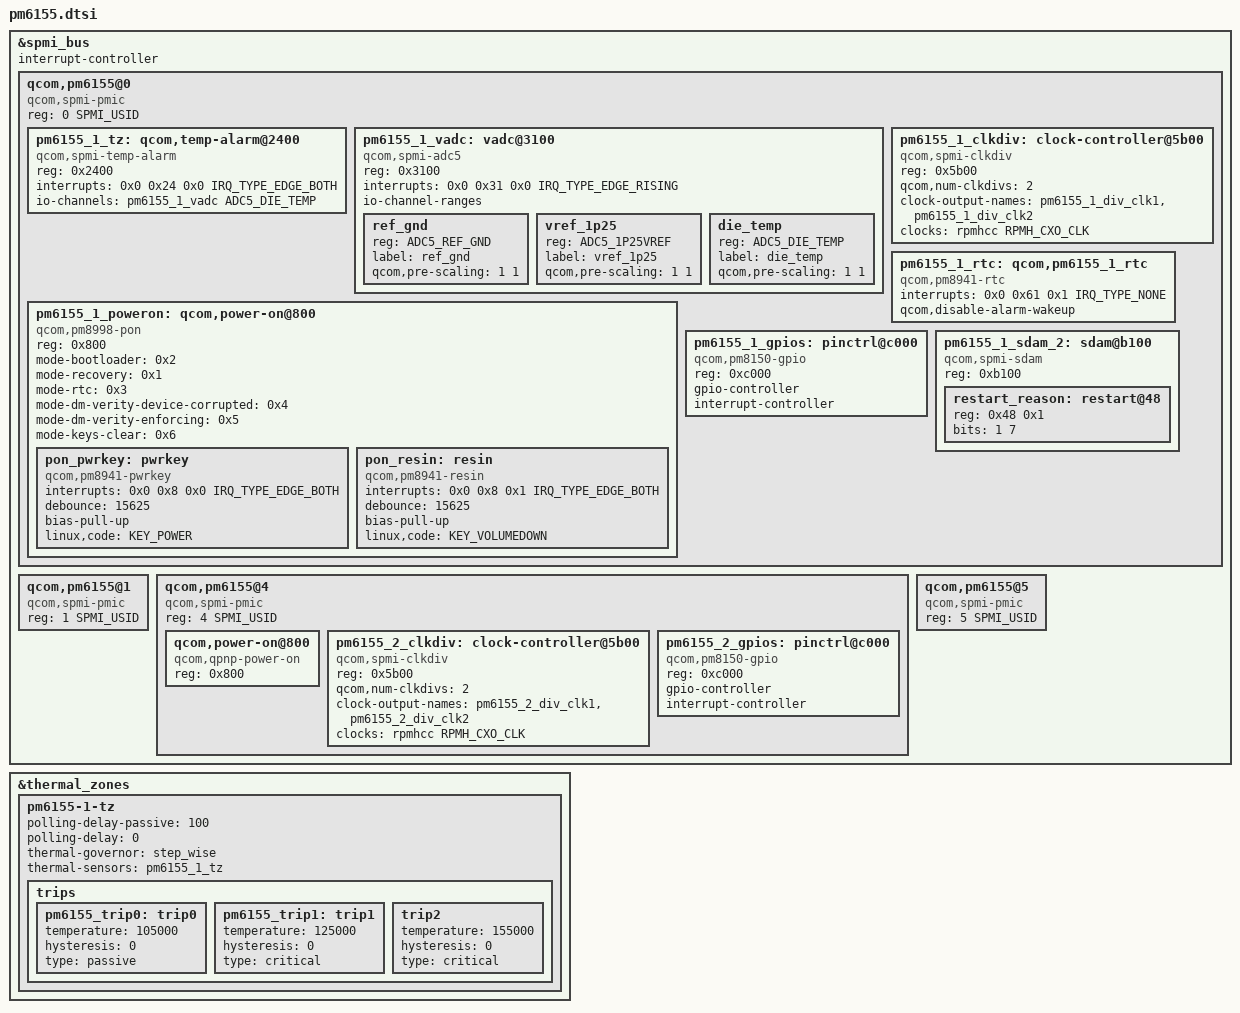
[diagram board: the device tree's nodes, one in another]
#include <dt-bindings/clock/qcom,rpmh.h>
#include <dt-bindings/input/input.h>
#include <dt-bindings/input/qcom,qpnp-power-on.h>
#include <dt-bindings/interrupt-controller/irq.h>
#include <dt-bindings/spmi/spmi.h>
#include <dt-bindings/iio/qcom,spmi-vadc.h>

&spmi_bus {
	#address-cells = <2>;
	#size-cells = <0>;
	interrupt-controller;
	#interrupt-cells = <4>;

	qcom,pm6155@0 {
		compatible = "qcom,spmi-pmic";
		reg = <0 SPMI_USID>;
		#address-cells = <1>;
		#size-cells = <0>;

		pm6155_1_tz: qcom,temp-alarm@2400 {
			compatible = "qcom,spmi-temp-alarm";
			reg = <0x2400>;
			interrupts = <0x0 0x24 0x0 IRQ_TYPE_EDGE_BOTH>;
			io-channels = <&pm6155_1_vadc ADC5_DIE_TEMP>;
			io-channel-names = "thermal";
			#thermal-sensor-cells = <0>;
		};

		pm6155_1_vadc: vadc@3100 {
			compatible = "qcom,spmi-adc5";
			reg = <0x3100>;
			#address-cells = <1>;
			#size-cells = <0>;
			interrupts = <0x0 0x31 0x0 IRQ_TYPE_EDGE_RISING>;
			interrupt-names = "eoc-int-en-set";
			#io-channel-cells = <1>;
			io-channel-ranges;

			/* Channel node */
			ref_gnd {
				reg = <ADC5_REF_GND>;
				label = "ref_gnd";
				qcom,pre-scaling = <1 1>;
			};

			vref_1p25 {
				reg = <ADC5_1P25VREF>;
				label = "vref_1p25";
				qcom,pre-scaling = <1 1>;
			};

			die_temp {
				reg = <ADC5_DIE_TEMP>;
				label = "die_temp";
				qcom,pre-scaling = <1 1>;
			};
		};

		pm6155_1_poweron: qcom,power-on@800 {
			compatible = "qcom,pm8998-pon";
			reg = <0x800>;
			mode-bootloader = <0x2>;
			mode-recovery = <0x1>;
			mode-rtc = <0x3>;
			mode-dm-verity-device-corrupted = <0x4>;
			mode-dm-verity-enforcing = <0x5>;
			mode-keys-clear = <0x6>;

			pon_pwrkey: pwrkey {
				compatible = "qcom,pm8941-pwrkey";
				interrupts = <0x0 0x8 0x0 IRQ_TYPE_EDGE_BOTH>;
				debounce = <15625>;
				bias-pull-up;
				linux,code = <KEY_POWER>;
			};

			pon_resin: resin {
				compatible = "qcom,pm8941-resin";
				interrupts = <0x0 0x8 0x1 IRQ_TYPE_EDGE_BOTH>;
				debounce = <15625>;
				bias-pull-up;
				linux,code = <KEY_VOLUMEDOWN>;
			};
		};

		pm6155_1_clkdiv: clock-controller@5b00 {
			compatible = "qcom,spmi-clkdiv";
			reg = <0x5b00>;
			#clock-cells = <1>;
			qcom,num-clkdivs = <2>;
			clock-output-names = "pm6155_1_div_clk1",
						"pm6155_1_div_clk2";
			clocks = <&rpmhcc RPMH_CXO_CLK>;
			clock-names = "xo";
		};

		pm6155_1_rtc: qcom,pm6155_1_rtc {
			compatible = "qcom,pm8941-rtc";
			interrupts = <0x0 0x61 0x1 IRQ_TYPE_NONE>;
			qcom,disable-alarm-wakeup;
		};

		pm6155_1_gpios: pinctrl@c000 {
			compatible = "qcom,pm8150-gpio";
			reg = <0xc000>;
			gpio-controller;
			#gpio-cells = <2>;
			interrupt-controller;
			#interrupt-cells = <2>;
		};

		pm6155_1_sdam_2: sdam@b100 {
			compatible = "qcom,spmi-sdam";
			reg = <0xb100>;
			#address-cells = <1>;
			#size-cells = <1>;

			restart_reason: restart@48 {
				reg = <0x48 0x1>;
				bits = <1 7>;
			};
		};

	};

	qcom,pm6155@1 {
		compatible ="qcom,spmi-pmic";
		reg = <1 SPMI_USID>;
		#address-cells = <1>;
		#size-cells = <0>;
	};

	/* below definitions are for the second instance of pm6155 */
	qcom,pm6155@4 {
		compatible = "qcom,spmi-pmic";
		reg = <4 SPMI_USID>;
		#address-cells = <1>;
		#size-cells = <0>;

		qcom,power-on@800 {
			compatible = "qcom,qpnp-power-on";
			reg = <0x800>;
		};

		pm6155_2_clkdiv: clock-controller@5b00 {
			compatible = "qcom,spmi-clkdiv";
			reg = <0x5b00>;
			#clock-cells = <1>;
			qcom,num-clkdivs = <2>;
			clock-output-names = "pm6155_2_div_clk1",
						"pm6155_2_div_clk2";
			clocks = <&rpmhcc RPMH_CXO_CLK>;
			clock-names = "xo";
		};

		pm6155_2_gpios: pinctrl@c000 {
			compatible = "qcom,pm8150-gpio";
			reg = <0xc000>;
			gpio-controller;
			#gpio-cells = <2>;
			interrupt-controller;
			#interrupt-cells = <2>;
		};
	};

	qcom,pm6155@5 {
		compatible ="qcom,spmi-pmic";
		reg = <5 SPMI_USID>;
		#address-cells = <1>;
		#size-cells = <0>;
	};
};

&thermal_zones {
	pm6155-1-tz {
		polling-delay-passive = <100>;
		polling-delay = <0>;
		thermal-governor = "step_wise";
		thermal-sensors = <&pm6155_1_tz>;

		trips {
			pm6155_trip0: trip0 {
				temperature = <105000>;
				hysteresis = <0>;
				type = "passive";
			};

			pm6155_trip1: trip1 {
				temperature = <125000>;
				hysteresis = <0>;
				type = "critical";
			};

			trip2 {
				temperature = <155000>;
				hysteresis = <0>;
				type = "critical";
			};
		};
	};
};
